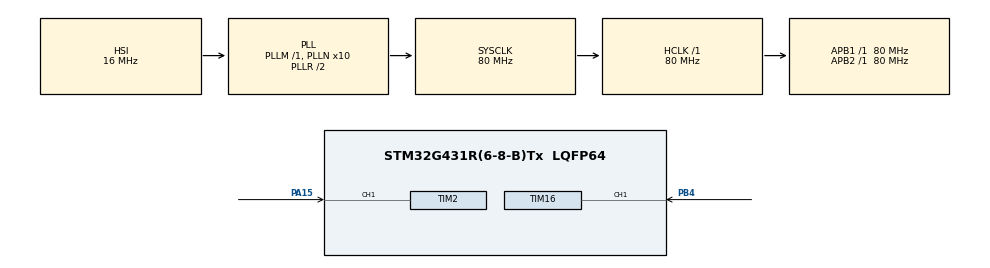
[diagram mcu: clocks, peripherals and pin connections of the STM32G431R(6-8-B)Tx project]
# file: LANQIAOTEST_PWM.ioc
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Mcu.Family=STM32G4
Mcu.Name=STM32G431R(6-8-B)Tx
Mcu.Package=LQFP64
NVIC.PriorityGroup=NVIC_PRIORITYGROUP_4
NVIC.TIM1_TRG_COM_TIM17_IRQn=true\:0\:0\:false\:false\:true\:true\:true\:true
NVIC.TIM1_UP_TIM16_IRQn=true\:0\:0\:false\:false\:true\:true\:true\:true
NVIC.TIM2_IRQn=true\:0\:0\:false\:false\:true\:true\:true\:true
PA13.Mode=Serial_Wire
PA13.Signal=SYS_JTMS-SWDIO
PA14.Mode=Serial_Wire
PA14.Signal=SYS_JTCK-SWCLK
PA15.Signal=S_TIM2_CH1
PB4.Signal=S_TIM16_CH1
PC14-OSC32_IN.Mode=LSE-External-Oscillator
PC14-OSC32_IN.Signal=RCC_OSC32_IN
PC15-OSC32_OUT.Mode=LSE-External-Oscillator
PC15-OSC32_OUT.Signal=RCC_OSC32_OUT
ProjectManager.HeapSize=0x200
ProjectManager.StackSize=0x400
ProjectManager.TargetToolchain=MDK-ARM V5.32
RCC.ADC12Freq_Value=80000000
RCC.AHBFreq_Value=80000000
RCC.APB1Freq_Value=80000000
RCC.APB1TimFreq_Value=80000000
RCC.APB2Freq_Value=80000000
RCC.APB2TimFreq_Value=80000000
RCC.CortexFreq_Value=80000000
RCC.EXTERNAL_CLOCK_VALUE=12288000
RCC.HCLKFreq_Value=80000000
RCC.HSE_VALUE=8000000
RCC.HSI48_VALUE=48000000
RCC.HSI_VALUE=16000000
RCC.PLLN=10
RCC.SYSCLKFreq_VALUE=80000000
RCC.SYSCLKSource=RCC_SYSCLKSOURCE_PLLCLK
RCC.USBFreq_Value=80000000
RCC.VCOOutputFreq_Value=160000000
SH.S_TIM16_CH1.0=TIM16_CH1,Input_Capture1_from_TI1
SH.S_TIM2_CH1.0=TIM2_CH1,Input_Capture1_from_TI1
TIM16.Channel=TIM_CHANNEL_1
TIM16.PeriodNoDither=65535
TIM16.Prescaler=80 - 1
TIM17.Prescaler=80 - 1
TIM2.Channel-Input_Capture1_from_TI1=TIM_CHANNEL_1
TIM2.PeriodNoDither=65535
TIM2.Prescaler=800 -1 
VP_SYS_VS_DBSignals.Mode=DisableDeadBatterySignals
VP_TIM16_VS_ClockSourceINT.Mode=Enable_Timer
VP_TIM17_VS_ClockSourceINT.Mode=Enable_Timer
VP_TIM2_VS_ClockSourceINT.Mode=Internal
board=custom

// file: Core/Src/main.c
/* USER CODE BEGIN Header */
/**
  ******************************************************************************
  * @file           : main.c
  * @brief          : Main program body
  ******************************************************************************
  * @attention
  *
  * Copyright (c) 2024 STMicroelectronics.
  * All rights reserved.
  *
  * This software is licensed under terms that can be found in the LICENSE file
  * in the root directory of this software component.
  * If no LICENSE file comes with this software, it is provided AS-IS.
  *
  ******************************************************************************
  */
/* USER CODE END Header */
#include "main.h"

TIM_HandleTypeDef htim2;
TIM_HandleTypeDef htim16;
TIM_HandleTypeDef htim17;

void SystemClock_Config(void);
static void MX_GPIO_Init(void);
static void MX_TIM2_Init(void);
static void MX_TIM17_Init(void);
static void MX_TIM16_Init(void);

int main(void)
{

  /* MCU Configuration--------------------------------------------------------*/

  /* Reset of all peripherals, Initializes the Flash interface and the Systick. */
  HAL_Init();

  /* Configure the system clock */
  SystemClock_Config();

  /* Initialize all configured peripherals */
  MX_GPIO_Init();
  MX_TIM2_Init();
  MX_TIM17_Init();
  MX_TIM16_Init();
  /* USER CODE BEGIN 2 */
  LCD_Init();
  LCD_Clear(Black);
  LCD_SetBackColor(Black);   //设置背景颜色 为 Black
  LCD_SetTextColor(White);   // 设置字体颜色
	HAL_TIM_PWM_Start(&htim2,TIM_CHANNEL_2); // 因为设置了TIM2的通道2
	TIM2->CCR2 = 50; // 设置 通道二的占空比

	HAL_TIM_IC_Start_IT(&htim16,TIM_CHANNEL_1);  //因为我设置了TIM16的输入捕获 并且是中断 这个不能忘记开启
	HAL_TIM_IC_Start_IT(&htim2,TIM_CHANNEL_1);  //因为我设置了TIM2的输入捕获 并且是中断 这个不能忘记开启
  /* USER CODE END 2 */

  /* Infinite loop */
  /* USER CODE BEGIN WHILE */
  while (1)
  {
	  lcd_show();
    /* USER CODE END WHILE */

  }
}

void SystemClock_Config(void)
{
  RCC_OscInitTypeDef RCC_OscInitStruct = {0};
  RCC_ClkInitTypeDef RCC_ClkInitStruct = {0};

  /** Configure the main internal regulator output voltage
  */
  HAL_PWREx_ControlVoltageScaling(PWR_REGULATOR_VOLTAGE_SCALE1);

  /** Initializes the RCC Oscillators according to the specified parameters
  * in the RCC_OscInitTypeDef structure.
  */
  RCC_OscInitStruct.OscillatorType = RCC_OSCILLATORTYPE_HSI;
  RCC_OscInitStruct.HSIState = RCC_HSI_ON;
  RCC_OscInitStruct.HSICalibrationValue = RCC_HSICALIBRATION_DEFAULT;
  RCC_OscInitStruct.PLL.PLLState = RCC_PLL_ON;
  RCC_OscInitStruct.PLL.PLLSource = RCC_PLLSOURCE_HSI;
  RCC_OscInitStruct.PLL.PLLM = RCC_PLLM_DIV1;
  RCC_OscInitStruct.PLL.PLLN = 10;
  RCC_OscInitStruct.PLL.PLLP = RCC_PLLP_DIV2;
  RCC_OscInitStruct.PLL.PLLQ = RCC_PLLQ_DIV2;
  RCC_OscInitStruct.PLL.PLLR = RCC_PLLR_DIV2;
  if (HAL_RCC_OscConfig(&RCC_OscInitStruct) != HAL_OK)
  {
    Error_Handler();
  }

  /** Initializes the CPU, AHB and APB buses clocks
  */
  RCC_ClkInitStruct.ClockType = RCC_CLOCKTYPE_HCLK|RCC_CLOCKTYPE_SYSCLK
                              |RCC_CLOCKTYPE_PCLK1|RCC_CLOCKTYPE_PCLK2;
  RCC_ClkInitStruct.SYSCLKSource = RCC_SYSCLKSOURCE_PLLCLK;
  RCC_ClkInitStruct.AHBCLKDivider = RCC_SYSCLK_DIV1;
  RCC_ClkInitStruct.APB1CLKDivider = RCC_HCLK_DIV1;
  RCC_ClkInitStruct.APB2CLKDivider = RCC_HCLK_DIV1;

  if (HAL_RCC_ClockConfig(&RCC_ClkInitStruct, FLASH_LATENCY_2) != HAL_OK)
  {
    Error_Handler();
  }
}

static void MX_TIM2_Init(void)
{

  TIM_ClockConfigTypeDef sClockSourceConfig = {0};
  TIM_MasterConfigTypeDef sMasterConfig = {0};
  TIM_IC_InitTypeDef sConfigIC = {0};

  htim2.Instance = TIM2;
  htim2.Init.Prescaler = 800 -1 ;
  htim2.Init.CounterMode = TIM_COUNTERMODE_UP;
  htim2.Init.Period = 65535;
  htim2.Init.ClockDivision = TIM_CLOCKDIVISION_DIV1;
  htim2.Init.AutoReloadPreload = TIM_AUTORELOAD_PRELOAD_DISABLE;
  if (HAL_TIM_Base_Init(&htim2) != HAL_OK)
  {
    Error_Handler();
  }
  sClockSourceConfig.ClockSource = TIM_CLOCKSOURCE_INTERNAL;
  if (HAL_TIM_ConfigClockSource(&htim2, &sClockSourceConfig) != HAL_OK)
  {
    Error_Handler();
  }
  if (HAL_TIM_IC_Init(&htim2) != HAL_OK)
  {
    Error_Handler();
  }
  sMasterConfig.MasterOutputTrigger = TIM_TRGO_RESET;
  sMasterConfig.MasterSlaveMode = TIM_MASTERSLAVEMODE_DISABLE;
  if (HAL_TIMEx_MasterConfigSynchronization(&htim2, &sMasterConfig) != HAL_OK)
  {
    Error_Handler();
  }
  sConfigIC.ICPolarity = TIM_INPUTCHANNELPOLARITY_RISING;
  sConfigIC.ICSelection = TIM_ICSELECTION_DIRECTTI;
  sConfigIC.ICPrescaler = TIM_ICPSC_DIV1;
  sConfigIC.ICFilter = 0;
  if (HAL_TIM_IC_ConfigChannel(&htim2, &sConfigIC, TIM_CHANNEL_1) != HAL_OK)
  {
    Error_Handler();
  }

}

static void MX_TIM16_Init(void)
{

  TIM_IC_InitTypeDef sConfigIC = {0};

  htim16.Instance = TIM16;
  htim16.Init.Prescaler = 80 - 1;
  htim16.Init.CounterMode = TIM_COUNTERMODE_UP;
  htim16.Init.Period = 65535;
  htim16.Init.ClockDivision = TIM_CLOCKDIVISION_DIV1;
  htim16.Init.RepetitionCounter = 0;
  htim16.Init.AutoReloadPreload = TIM_AUTORELOAD_PRELOAD_DISABLE;
  if (HAL_TIM_Base_Init(&htim16) != HAL_OK)
  {
    Error_Handler();
  }
  if (HAL_TIM_IC_Init(&htim16) != HAL_OK)
  {
    Error_Handler();
  }
  sConfigIC.ICPolarity = TIM_INPUTCHANNELPOLARITY_RISING;
  sConfigIC.ICSelection = TIM_ICSELECTION_DIRECTTI;
  sConfigIC.ICPrescaler = TIM_ICPSC_DIV1;
  sConfigIC.ICFilter = 0;
  if (HAL_TIM_IC_ConfigChannel(&htim16, &sConfigIC, TIM_CHANNEL_1) != HAL_OK)
  {
    Error_Handler();
  }

}

static void MX_TIM17_Init(void)
{

  htim17.Instance = TIM17;
  htim17.Init.Prescaler = 80 - 1;
  htim17.Init.CounterMode = TIM_COUNTERMODE_UP;
  htim17.Init.Period = 65535;
  htim17.Init.ClockDivision = TIM_CLOCKDIVISION_DIV1;
  htim17.Init.RepetitionCounter = 0;
  htim17.Init.AutoReloadPreload = TIM_AUTORELOAD_PRELOAD_DISABLE;
  if (HAL_TIM_Base_Init(&htim17) != HAL_OK)
  {
    Error_Handler();
  }

}

static void MX_GPIO_Init(void)
{

  /* GPIO Ports Clock Enable */
  __HAL_RCC_GPIOC_CLK_ENABLE();
  __HAL_RCC_GPIOA_CLK_ENABLE();
  __HAL_RCC_GPIOB_CLK_ENABLE();

}

void Error_Handler(void)
{
  __disable_irq();
  while (1)
  {
  }
}
